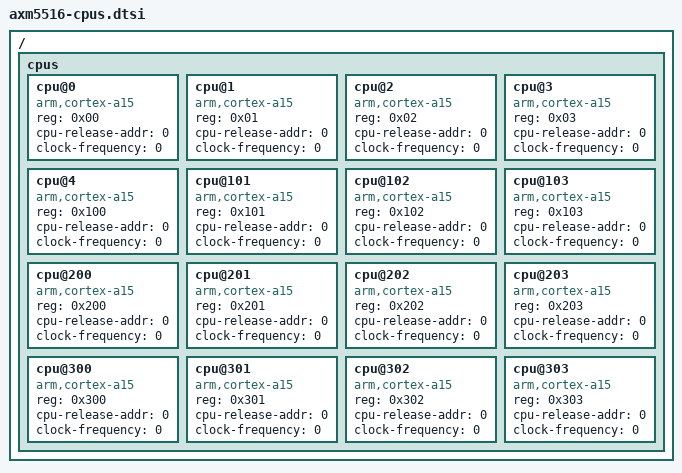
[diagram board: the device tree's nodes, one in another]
// SPDX-License-Identifier: GPL-2.0-only
// Copyright (C) 2021 INTEL Corporation

/ {
	cpus {
		#address-cells = <1>;
		#size-cells = <0>;

		cpu@0 {
			device_type = "cpu";
			compatible = "arm,cortex-a15";
			reg = <0x00>;
			cpu-release-addr = <0>; // Fixed by the boot loader
			clock-frequency = <0>;  // Placeholder
		};

		cpu@1 {
			device_type = "cpu";
			compatible = "arm,cortex-a15";
			reg = <0x01>;
			cpu-release-addr = <0>; // Fixed by the boot loader
			clock-frequency = <0>;  // Placeholder
		};

		cpu@2 {
			device_type = "cpu";
			compatible = "arm,cortex-a15";
			reg = <0x02>;
			cpu-release-addr = <0>; // Fixed by the boot loader
			clock-frequency = <0>;  // Placeholder
		};

		cpu@3 {
			device_type = "cpu";
			compatible = "arm,cortex-a15";
			reg = <0x03>;
			cpu-release-addr = <0>; // Fixed by the boot loader
			clock-frequency = <0>;  // Placeholder
		};

		cpu@4 {
			device_type = "cpu";
			compatible = "arm,cortex-a15";
			reg = <0x100>;
			cpu-release-addr = <0>; // Fixed by the boot loader
			clock-frequency = <0>;  // Placeholder
		};

		cpu@101 {
			device_type = "cpu";
			compatible = "arm,cortex-a15";
			reg = <0x101>;
			cpu-release-addr = <0>; // Fixed by the boot loader
			clock-frequency = <0>;  // Placeholder
		};

		cpu@102 {
			device_type = "cpu";
			compatible = "arm,cortex-a15";
			reg = <0x102>;
			cpu-release-addr = <0>; // Fixed by the boot loader
			clock-frequency = <0>;  // Placeholder
		};

		cpu@103 {
			device_type = "cpu";
			compatible = "arm,cortex-a15";
			reg = <0x103>;
			cpu-release-addr = <0>; // Fixed by the boot loader
			clock-frequency = <0>;  // Placeholder
		};

		cpu@200 {
			device_type = "cpu";
			compatible = "arm,cortex-a15";
			reg = <0x200>;
			cpu-release-addr = <0>; // Fixed by the boot loader
			clock-frequency = <0>;  // Placeholder
		};

		cpu@201 {
			device_type = "cpu";
			compatible = "arm,cortex-a15";
			reg = <0x201>;
			cpu-release-addr = <0>; // Fixed by the boot loader
			clock-frequency = <0>;  // Placeholder
		};

		cpu@202 {
			device_type = "cpu";
			compatible = "arm,cortex-a15";
			reg = <0x202>;
			cpu-release-addr = <0>; // Fixed by the boot loader
			clock-frequency = <0>;  // Placeholder
		};

		cpu@203 {
			device_type = "cpu";
			compatible = "arm,cortex-a15";
			reg = <0x203>;
			cpu-release-addr = <0>; // Fixed by the boot loader
			clock-frequency = <0>;  // Placeholder
		};

		cpu@300 {
			device_type = "cpu";
			compatible = "arm,cortex-a15";
			reg = <0x300>;
			cpu-release-addr = <0>; // Fixed by the boot loader
			clock-frequency = <0>;  // Placeholder
		};

		cpu@301 {
			device_type = "cpu";
			compatible = "arm,cortex-a15";
			reg = <0x301>;
			cpu-release-addr = <0>; // Fixed by the boot loader
			clock-frequency = <0>;  // Placeholder
		};

		cpu@302 {
			device_type = "cpu";
			compatible = "arm,cortex-a15";
			reg = <0x302>;
			cpu-release-addr = <0>; // Fixed by the boot loader
			clock-frequency = <0>;  // Placeholder
		};

		cpu@303 {
			device_type = "cpu";
			compatible = "arm,cortex-a15";
			reg = <0x303>;
			cpu-release-addr = <0>; // Fixed by the boot loader
			clock-frequency = <0>;  // Placeholder
		};
	};
};
